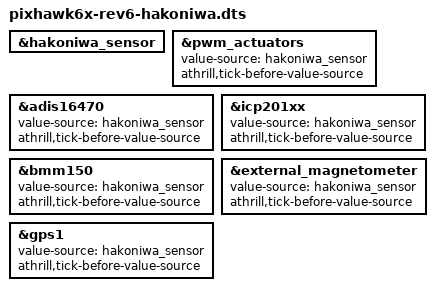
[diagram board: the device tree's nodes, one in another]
/* SPDX-License-Identifier: MIT */

#include "pixhawk6x-rev6.dts"

&hakoniwa_sensor { status = "okay"; };
&pwm_actuators {
	value-source = <&hakoniwa_sensor>;
	athrill,tick-before-value-source;
};
&adis16470 {
	value-source = <&hakoniwa_sensor>;
	athrill,tick-before-value-source;
};
&icp201xx {
	value-source = <&hakoniwa_sensor>;
	athrill,tick-before-value-source;
};
&bmm150 {
	value-source = <&hakoniwa_sensor>;
	athrill,tick-before-value-source;
};
&external_magnetometer {
	value-source = <&hakoniwa_sensor>;
	athrill,tick-before-value-source;
};
&gps1 {
	value-source = <&hakoniwa_sensor>;
	athrill,tick-before-value-source;
};
